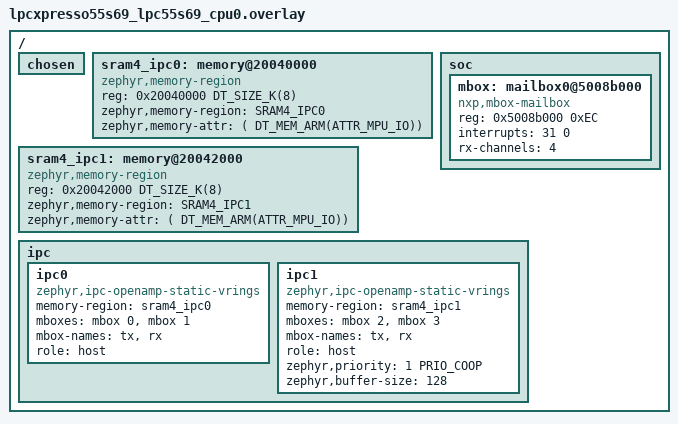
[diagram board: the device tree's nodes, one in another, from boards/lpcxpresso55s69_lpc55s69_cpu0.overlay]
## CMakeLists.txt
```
#
# Copyright (c) 2021 Carlo Caione <ccaione@baylibre.com>
# Copyright 2024 NXP
#
# SPDX-License-Identifier: Apache-2.0
#

cmake_minimum_required(VERSION 3.20.0)

find_package(Zephyr REQUIRED HINTS $ENV{ZEPHYR_BASE})

set(REMOTE_ZEPHYR_DIR ${CMAKE_CURRENT_BINARY_DIR}/../remote/zephyr)

if(NOT (CONFIG_BOARD_NRF5340DK_NRF5340_CPUAPP OR
        CONFIG_BOARD_LPCXPRESSO55S69_LPC55S69_CPU0 OR
        CONFIG_BOARD_MIMXRT1160_EVK_MIMXRT1166_CM7 OR
        CONFIG_BOARD_MIMXRT1170_EVK_MIMXRT1176_CM7
       )
  )
  message(FATAL_ERROR "${BOARD} is not supported for this sample")
endif()

project(ipc_service)

if(CONFIG_INCLUDE_REMOTE_DIR)
  target_include_directories(zephyr_interface
    INTERFACE ${REMOTE_ZEPHYR_DIR}/include/public)
endif()

target_sources(app PRIVATE src/main.c)

include(ExternalProject)
```

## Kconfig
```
# Copyright 2024 NXP
#
# SPDX-License-Identifier: Apache-2.0

source "Kconfig.zephyr"

config INCLUDE_REMOTE_DIR
	bool "Include remote core header directory"
	help
	  Include remote build header files. Can be used if primary image
	  needs to be aware of size or base address of secondary image
```

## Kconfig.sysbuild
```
# Copyright 2023 Nordic Semiconductor ASA
# Copyright 2024 NXP
#
# SPDX-License-Identifier: Apache-2.0

source "share/sysbuild/Kconfig"

config NET_CORE_BOARD
string
	default "nrf5340dk/nrf5340/cpunet" if $(BOARD) = "nrf5340dk"
	default "lpcxpresso55s69/lpc55s69/cpu1" if $(BOARD) = "lpcxpresso55s69"
	default "mimxrt1160_evk/mimxrt1166/cm4" if $(BOARD) = "mimxrt1160_evk"
	default "mimxrt1170_evk/mimxrt1176/cm4" if $(BOARD) = "mimxrt1170_evk"
	default "mimxrt1170_evkb/mimxrt1176/cm4" if $(BOARD) = "mimxrt1170_evkb"
```

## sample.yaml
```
sample:
  name: IPC Service example integration (OpenAMP static_vrings backend)
tests:
  sample.ipc.static_vrings:
    platform_allow:
      - nrf5340dk/nrf5340/cpuapp
      - lpcxpresso55s69/lpc55s69/cpu0
      - mimxrt1160_evk/mimxrt1166/cm7
      - mimxrt1170_evk/mimxrt1176/cm7
      - mimxrt1170_evk@B/mimxrt1176/cm7
    integration_platforms:
      - nrf5340dk/nrf5340/cpuapp
    tags: ipc
    sysbuild: true
    harness: console
    harness_config:
      type: multi_line
      ordered: false
      regex:
        - "IPC-service HOST \\[INST 0 - ENDP A\\] demo started"
        - "IPC-service HOST \\[INST 0 - ENDP B\\] demo started"
        - "IPC-service HOST \\[INST 1\\] demo started"
        - "IPC-service HOST \\[INST 0 - ENDP A\\] demo ended\\."
        - "IPC-service HOST \\[INST 0 - ENDP B\\] demo ended\\."
        - "IPC-service HOST \\[INST 1\\] demo ended\\."
```

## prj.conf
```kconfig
CONFIG_PRINTK=y
CONFIG_HEAP_MEM_POOL_SIZE=4096

CONFIG_IPC_SERVICE=y
CONFIG_MBOX=y

CONFIG_OPENAMP=y
CONFIG_OPENAMP_SLAVE=n

CONFIG_LOG=y
CONFIG_IPC_SERVICE_LOG_LEVEL_INF=y
```

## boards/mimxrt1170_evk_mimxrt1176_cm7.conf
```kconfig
CONFIG_MBOX_NXP_IMX_MU=y
CONFIG_SECOND_CORE_MCUX=y
CONFIG_INCLUDE_REMOTE_DIR=y
```

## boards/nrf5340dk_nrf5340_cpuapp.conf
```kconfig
CONFIG_BOARD_ENABLE_CPUNET=y
CONFIG_MBOX_NRFX_IPC=y
```

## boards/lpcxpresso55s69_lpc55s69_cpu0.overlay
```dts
/*
 * Copyright 2024 NXP
 *
 * SPDX-License-Identifier: Apache-2.0
 */

#include <zephyr/dt-bindings/ipc_service/static_vrings.h>
#include <zephyr/dt-bindings/memory-attr/memory-attr-arm.h>

/ {
	chosen {
		/* Delete ipc chosen property where old IPM mailbox driver bellow is
		 * configured.
		 */
		/delete-property/ zephyr,ipc;
		/delete-property/ zephyr,ipc_shm;
	};

	/* Define memory regions for IPC
	 * Note that shared memory must have specific MPU attributes set.
	 */
	sram4_ipc0: memory@20040000{
		compatible = "zephyr,memory-region", "mmio-sram";
		reg = <0x20040000 DT_SIZE_K(8)>;
		zephyr,memory-region="SRAM4_IPC0";
		zephyr,memory-attr = <( DT_MEM_ARM(ATTR_MPU_IO))>;
	};

	sram4_ipc1: memory@20042000{
		compatible = "zephyr,memory-region", "mmio-sram";
		reg = <0x20042000 DT_SIZE_K(8)>;
		zephyr,memory-region="SRAM4_IPC1";
		zephyr,memory-attr = <( DT_MEM_ARM(ATTR_MPU_IO))>;
	};

	soc {
		/* Delete IPM Driver node nxp,lpc-mailbox */
		/delete-node/ mailbox@8b000;

		/* Attach MBOX driver to Mailbox Unit */
		mbox:mailbox0@5008b000 {
			compatible = "nxp,mbox-mailbox";
			reg = <0x5008b000 0xEC>;
			interrupts = <31 0>;
			rx-channels = <4>;
			#mbox-cells = <1>;
			status = "okay";
		};
	 };

	ipc {
		/delete-node/ ipc0;

		ipc0: ipc0 {
			compatible = "zephyr,ipc-openamp-static-vrings";
			memory-region = <&sram4_ipc0>;
			mboxes = <&mbox 0>, <&mbox 1>;
			mbox-names = "tx", "rx";
			role = "host";
			status = "okay";
		};

		ipc1: ipc1 {
			compatible = "zephyr,ipc-openamp-static-vrings";
			memory-region = <&sram4_ipc1>;
			mboxes = <&mbox 2>, <&mbox 3>;
			mbox-names = "tx", "rx";
			role = "host";
			zephyr,priority = <1 PRIO_COOP>;
			zephyr,buffer-size = <128>;
			status = "okay";
		 };
	 };
 };
```

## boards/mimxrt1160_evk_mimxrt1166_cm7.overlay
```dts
/*
 * Copyright 2024 NXP
 *
 * SPDX-License-Identifier: Apache-2.0
 */

#include <zephyr/dt-bindings/ipc_service/static_vrings.h>
#include <zephyr/dt-bindings/memory-attr/memory-attr-arm.h>

/ {
	chosen {
		/* Delete ipc chosen property where old IPM mailbox driver bellow is
		 * configured.
		 */
		/delete-property/ zephyr,ipc;
		/delete-property/ zephyr,ipc_shm;

		zephyr,console = &lpuart1;
		zephyr,shell-uart = &lpuart1;
	};

	/* Define memory regions for IPC
	 * Note that shared memory must have specific MPU attributes set.
	 */
	 ocram2_ipc0: memory@202c0000{
		compatible = "zephyr,memory-region", "mmio-sram";
		reg = <0x202c0000 DT_SIZE_K(32)>;
		zephyr,memory-region="OCRAM2_IPC0";
		zephyr,memory-attr = <( DT_MEM_ARM(ATTR_MPU_IO))>;
	};
	ocram2_ipc1: memory@202c8000{
		compatible = "zephyr,memory-region", "mmio-sram";
		reg = <0x202c8000 DT_SIZE_K(32)>;
		zephyr,memory-region="OCRAM2_IPC1";
		zephyr,memory-attr = <( DT_MEM_ARM(ATTR_MPU_IO))>;
	};

	soc {
		/* Delete IPM Driver node nxp,imx-mu */
		/delete-node/ mailbox@40c48000;

		/* Attach MBOX driver to MU Unit */
		mbox:mbox@40c48000 {
			compatible = "nxp,mbox-imx-mu";
			reg = <0x40c48000 0x4000>;
			interrupts = <118 0>;
			rx-channels = <4>;
			#mbox-cells = <1>;
			status = "okay";
		};
	};

	ipc {
		/delete-node/ ipc0;

		ipc0: ipc0 {
			compatible = "zephyr,ipc-openamp-static-vrings";
			memory-region = <&ocram2_ipc0>;
			mboxes = <&mbox 0>, <&mbox 1>;
			mbox-names = "tx", "rx";
			role = "host";
			status = "okay";
		};

		ipc1: ipc1 {
			compatible = "zephyr,ipc-openamp-static-vrings";
			memory-region = <&ocram2_ipc1>;
			mboxes = <&mbox 2>, <&mbox 3>;
			mbox-names = "tx", "rx";
			role = "host";
			zephyr,priority = <1 PRIO_COOP>;
			zephyr,buffer-size = <128>;
			status = "okay";
		};
	};
};
```

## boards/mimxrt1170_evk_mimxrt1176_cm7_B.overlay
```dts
/*
 * Copyright 2024 NXP
 *
 * SPDX-License-Identifier: Apache-2.0
 */

#include <zephyr/dt-bindings/ipc_service/static_vrings.h>
#include <zephyr/dt-bindings/memory-attr/memory-attr-arm.h>

/ {
	chosen {
		/* Delete ipc chosen property where old IPM mailbox driver bellow is
		 * configured.
		 */
		/delete-property/ zephyr,ipc;
		/delete-property/ zephyr,ipc_shm;

		zephyr,console = &lpuart1;
		zephyr,shell-uart = &lpuart1;
	};

	/* Define memory regions for IPC
	 * Note that shared memory must have specific MPU attributes set.
	 */
	ocram2_ipc0: memory@202c0000{
		compatible = "zephyr,memory-region", "mmio-sram";
		reg = <0x202c0000 DT_SIZE_K(32)>;
		zephyr,memory-region="OCRAM2_IPC0";
		zephyr,memory-attr = <( DT_MEM_ARM(ATTR_MPU_IO))>;
	};
	ocram2_ipc1: memory@202c8000{
		compatible = "zephyr,memory-region", "mmio-sram";
		reg = <0x202c8000 DT_SIZE_K(32)>;
		zephyr,memory-region="OCRAM2_IPC1";
		zephyr,memory-attr = <( DT_MEM_ARM(ATTR_MPU_IO))>;
	};

	soc {
		/* Delete IPM Driver node nxp,imx-mu */
		/delete-node/ mailbox@40c48000;

		/* Attach MBOX driver to MU Unit */
		mbox:mbox@40c48000 {
			compatible = "nxp,mbox-imx-mu";
			reg = <0x40c48000 0x4000>;
			interrupts = <118 0>;
			rx-channels = <4>;
			#mbox-cells = <1>;
			status = "okay";
		};
	};

	ipc {
		/delete-node/ ipc0;

		ipc0: ipc0 {
			compatible = "zephyr,ipc-openamp-static-vrings";
			memory-region = <&ocram2_ipc0>;
			mboxes = <&mbox 0>, <&mbox 1>;
			mbox-names = "tx", "rx";
			role = "host";
			status = "okay";
		};

		ipc1: ipc1 {
			compatible = "zephyr,ipc-openamp-static-vrings";
			memory-region = <&ocram2_ipc1>;
			mboxes = <&mbox 2>, <&mbox 3>;
			mbox-names = "tx", "rx";
			role = "host";
			zephyr,priority = <1 PRIO_COOP>;
			zephyr,buffer-size = <128>;
			status = "okay";
		};
	};
};
```

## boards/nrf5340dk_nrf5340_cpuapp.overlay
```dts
/*
 * Copyright (c) 2021 Carlo Caione <ccaione@baylibre.com>
 *
 * SPDX-License-Identifier: Apache-2.0
 */

#include <zephyr/dt-bindings/ipc_service/static_vrings.h>

/ {
	chosen {
		/delete-property/ zephyr,ipc_shm;
	};

	reserved-memory {
		/delete-node/ memory@20070000;

		sram_ipc0: memory@20070000 {
			reg = <0x20070000 0x8000>;
		};

		sram_ipc1: memory@20078000 {
			reg = <0x20078000 0x8000>;
		};
	};

	ipc {
		/delete-node/ ipc0;

		ipc0: ipc0 {
			compatible = "zephyr,ipc-openamp-static-vrings";
			memory-region = <&sram_ipc0>;
			mboxes = <&mbox 0>, <&mbox 1>;
			mbox-names = "tx", "rx";
			role = "host";
			status = "okay";

			bt_hci_ipc0: bt_hci_ipc0 {
				compatible = "zephyr,bt-hci-ipc";
				status = "okay";
			};
		};

		ipc1: ipc1 {
			compatible = "zephyr,ipc-openamp-static-vrings";
			memory-region = <&sram_ipc1>;
			mboxes = <&mbox 2>, <&mbox 3>;
			mbox-names = "tx", "rx";
			role = "host";
			zephyr,priority = <1 PRIO_COOP>;
			zephyr,buffer-size = <128>;
			status = "okay";
		};
	};
};
```

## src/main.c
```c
/*
 * Copyright (c) 2021 Carlo Caione <ccaione@baylibre.com>
 *
 * SPDX-License-Identifier: Apache-2.0
 */

#include <zephyr/kernel.h>
#include <zephyr/device.h>

#include <zephyr/ipc/ipc_service.h>

#define STACKSIZE	(4096)
#define PRIORITY	K_PRIO_PREEMPT(2)

K_THREAD_STACK_DEFINE(ipc0A_stack, STACKSIZE);
K_THREAD_STACK_DEFINE(ipc0B_stack, STACKSIZE);
K_THREAD_STACK_DEFINE(ipc1_stack, STACKSIZE);

static volatile uint8_t ipc0A_received_data;
static volatile uint8_t ipc0B_received_data;
static volatile uint8_t ipc1_received_data;

static K_SEM_DEFINE(ipc0A_bound_sem, 0, 1);
static K_SEM_DEFINE(ipc0B_bound_sem, 0, 1);
static K_SEM_DEFINE(ipc1_bound_sem, 0, 1);

static K_SEM_DEFINE(ipc0A_data_sem, 0, 1);
static K_SEM_DEFINE(ipc0B_data_sem, 0, 1);
static K_SEM_DEFINE(ipc1_data_sem, 0, 1);

/*
 * ==> THREAD 0A (IPC instance 0 - endpoint A) <==
 */

static void ipc0A_ept_bound(void *priv)
{
	k_sem_give(&ipc0A_bound_sem);
}

static void ipc0A_ept_recv(const void *data, size_t len, void *priv)
{
	ipc0A_received_data = *((uint8_t *) data);

	k_sem_give(&ipc0A_data_sem);
}

static struct ipc_ept_cfg ipc0A_ept_cfg = {
	.name = "ipc0A",
	.cb = {
		.bound    = ipc0A_ept_bound,
		.received = ipc0A_ept_recv,
	},
};

static void ipc0A_entry(void *dummy0, void *dummy1, void *dummy2)
{
	ARG_UNUSED(dummy0);
	ARG_UNUSED(dummy1);
	ARG_UNUSED(dummy2);

	const struct device *ipc0_instance;
	unsigned char message = 0;
	struct ipc_ept ipc0A_ept;
	int ret;

	printk("IPC-service HOST [INST 0 - ENDP A] demo started\n");

	ipc0_instance = DEVICE_DT_GET(DT_NODELABEL(ipc0));

	ret = ipc_service_open_instance(ipc0_instance);
	if (ret < 0 && ret != -EALREADY) {
		printk("ipc_service_open_instance() failure\n");
		return;
	}

	/*
	 * Wait 1 sec to give the opportunity to the SECONDARY core to register
	 * the endpoint first
	 */

	k_sleep(K_MSEC(1000));

	ret = ipc_service_register_endpoint(ipc0_instance, &ipc0A_ept, &ipc0A_ept_cfg);
	if (ret < 0) {
		printf("ipc_service_register_endpoint() failure\n");
		return;
	}

	k_sem_take(&ipc0A_bound_sem, K_FOREVER);

	while (message < 100) {
		ret = ipc_service_send(&ipc0A_ept, &message, sizeof(message));
		if (ret < 0) {
			printk("send_message(%d) failed with ret %d\n", message, ret);
			break;
		}

		k_sem_take(&ipc0A_data_sem, K_FOREVER);
		message = ipc0A_received_data;

		printk("HOST [0A]: %d\n", message);
		message++;
	}

	printk("IPC-service HOST [INST 0 - ENDP A] demo ended.\n");
}
K_THREAD_DEFINE(ipc0A_thread_id, STACKSIZE, ipc0A_entry, NULL, NULL, NULL, PRIORITY, 0, 0);

/*
 * ==> THREAD 0B (IPC instance 0 - endpoint B) <==
 */

static void ipc0B_ept_bound(void *priv)
{
	k_sem_give(&ipc0B_bound_sem);
}

static void ipc0B_ept_recv(const void *data, size_t len, void *priv)
{
	ipc0B_received_data = *((uint8_t *) data);

	k_sem_give(&ipc0B_data_sem);
}

static struct ipc_ept_cfg ipc0B_ept_cfg = {
	.name = "ipc0B",
	.cb = {
		.bound    = ipc0B_ept_bound,
		.received = ipc0B_ept_recv,
	},
};

static void ipc0B_entry(void *dummy0, void *dummy1, void *dummy2)
{
	ARG_UNUSED(dummy0);
	ARG_UNUSED(dummy1);
	ARG_UNUSED(dummy2);

	const struct device *ipc0_instance;
	unsigned char message = 0;
	struct ipc_ept ipc0B_ept;
	int ret;

	printk("IPC-service HOST [INST 0 - ENDP B] demo started\n");

	ipc0_instance = DEVICE_DT_GET(DT_NODELABEL(ipc0));

	ret = ipc_service_open_instance(ipc0_instance);
	if (ret < 0 && ret != -EALREADY) {
		printk("ipc_service_open_instance() failure\n");
		return;
	}

	ret = ipc_service_register_endpoint(ipc0_instance, &ipc0B_ept, &ipc0B_ept_cfg);
	if (ret < 0) {
		printf("ipc_service_register_endpoint() failure\n");
		return;
	}

	k_sem_take(&ipc0B_bound_sem, K_FOREVER);

	while (message < 100) {
		ret = ipc_service_send(&ipc0B_ept, &message, sizeof(message));
		if (ret < 0) {
			printk("send_message(%d) failed with ret %d\n", message, ret);
			break;
		}

		k_sem_take(&ipc0B_data_sem, K_FOREVER);
		message = ipc0B_received_data;

		printk("HOST [0B]: %d\n", message);
		message++;
	}

	printk("IPC-service HOST [INST 0 - ENDP B] demo ended.\n");
}
K_THREAD_DEFINE(ipc0B_thread_id, STACKSIZE, ipc0B_entry, NULL, NULL, NULL, PRIORITY, 0, 0);

/*
 * ==> THREAD 1 (IPC instance 1) <==
 *
 * NOTE: This instance is using the NOCOPY copability of the backend.
 */

static struct ipc_ept ipc1_ept;
static void *recv_data;

static void ipc1_ept_bound(void *priv)
{
	k_sem_give(&ipc1_bound_sem);
}

static void ipc1_ept_recv(const void *data, size_t len, void *priv)
{
	int ret;

	ret = ipc_service_hold_rx_buffer(&ipc1_ept, (void *) data);
	if (ret < 0) {
		printk("ipc_service_hold_rx_buffer failed with ret %d\n", ret);
	}

	/*
	 * This will only support a synchronous request-answer mechanism. For
	 * asynchronous cases a chain list should be implemented.
	 */
	recv_data = (void *) data;

	k_sem_give(&ipc1_data_sem);
}

static struct ipc_ept_cfg ipc1_ept_cfg = {
	.name = "ipc1",
	.cb = {
		.bound    = ipc1_ept_bound,
		.received = ipc1_ept_recv,
	},
};

static void ipc1_entry(void *dummy0, void *dummy1, void *dummy2)
{
	ARG_UNUSED(dummy0);
	ARG_UNUSED(dummy1);
	ARG_UNUSED(dummy2);

	const struct device *ipc1_instance;
	unsigned char message = 0;
	int ret;

	printk("IPC-service HOST [INST 1] demo started\n");

	ipc1_instance = DEVICE_DT_GET(DT_NODELABEL(ipc1));

	ret = ipc_service_open_instance(ipc1_instance);
	if (ret < 0 && ret != -EALREADY) {
		printk("ipc_service_open_instance() failure\n");
		return;
	}

	ret = ipc_service_register_endpoint(ipc1_instance, &ipc1_ept, &ipc1_ept_cfg);
	if (ret < 0) {
		printf("ipc_service_register_endpoint() failure\n");
		return;
	}

	k_sem_take(&ipc1_bound_sem, K_FOREVER);

	while (message < 50) {
		uint32_t len = 0;
		void *data;

		ret = ipc_service_get_tx_buffer(&ipc1_ept, &data, &len, K_FOREVER);
		if (ret < 0) {
			printk("ipc_service_get_tx_buffer failed with ret %d\n", ret);
			break;
		}

		if (message != 0) {
			*((unsigned char *) data) = *((unsigned char *) recv_data) + 1;

			ret = ipc_service_release_rx_buffer(&ipc1_ept, recv_data);
			if (ret < 0) {
				printk("ipc_service_release_rx_buffer failed with ret %d\n", ret);
				break;
			}
		} else {
			*((unsigned char *) data) = 0;
		}

		ret = ipc_service_send_nocopy(&ipc1_ept, data, sizeof(unsigned char));
		if (ret < 0) {
			printk("send_message(%d) failed with ret %d\n", message, ret);
			break;
		}

		k_sem_take(&ipc1_data_sem, K_FOREVER);

		printk("HOST [1]: %d\n", *((unsigned char *) recv_data));

		message++;
	}

	printk("IPC-service HOST [INST 1] demo ended.\n");
}
K_THREAD_DEFINE(ipc1_thread_id, STACKSIZE, ipc1_entry, NULL, NULL, NULL, PRIORITY, 0, 0);
```
